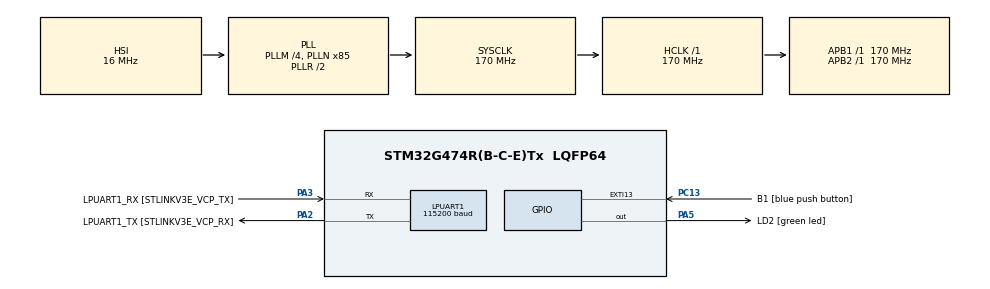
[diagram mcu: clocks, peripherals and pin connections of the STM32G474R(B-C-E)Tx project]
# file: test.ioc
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LPUART1.BaudRate=115200
LPUART1.WordLength=UART_WORDLENGTH_8B
Mcu.Family=STM32G4
Mcu.Name=STM32G474R(B-C-E)Tx
Mcu.Package=LQFP64
NVIC.EXTI15_10_IRQn=true\:0\:0\:false\:false\:true\:true\:true
NVIC.PriorityGroup=NVIC_PRIORITYGROUP_4
PA13.GPIO_Label=T_SWDIO
PA13.Mode=Trace_Asynchronous_SW
PA13.Signal=SYS_JTMS-SWDIO
PA14.GPIO_Label=T_SWCLK
PA14.Mode=Trace_Asynchronous_SW
PA14.Signal=SYS_JTCK-SWCLK
PA2.GPIO_Label=LPUART1_TX [STLINKV3E_VCP_RX]
PA2.Mode=Asynchronous
PA2.Signal=LPUART1_TX
PA3.GPIO_Label=LPUART1_RX [STLINKV3E_VCP_TX]
PA3.Mode=Asynchronous
PA3.Signal=LPUART1_RX
PA5.GPIO_Label=LD2 [green led]
PA5.Signal=GPIO_Output
PB3.GPIO_Label=T_SWO
PB3.Mode=Trace_Asynchronous_SW
PB3.Signal=SYS_JTDO-SWO
PC13.GPIO_Label=B1 [blue push button]
PC13.Signal=GPXTI13
PC14-OSC32_IN.Mode=LSE-External-Oscillator
PC14-OSC32_IN.Signal=RCC_OSC32_IN
PC15-OSC32_OUT.Mode=LSE-External-Oscillator
PC15-OSC32_OUT.Signal=RCC_OSC32_OUT
PF0-OSC_IN.Mode=HSE-External-Oscillator
PF0-OSC_IN.Signal=RCC_OSC_IN
PF1-OSC_OUT.Mode=HSE-External-Oscillator
PF1-OSC_OUT.Signal=RCC_OSC_OUT
ProjectManager.HeapSize=0x200
ProjectManager.StackSize=0x400
ProjectManager.TargetToolchain=Makefile
RCC.ADC12Freq_Value=170000000
RCC.ADC345Freq_Value=170000000
RCC.AHBFreq_Value=170000000
RCC.APB1Freq_Value=170000000
RCC.APB1TimFreq_Value=170000000
RCC.APB2Freq_Value=170000000
RCC.APB2TimFreq_Value=170000000
RCC.CortexFreq_Value=170000000
RCC.EXTERNAL_CLOCK_VALUE=12288000
RCC.HCLKFreq_Value=170000000
RCC.HSE_VALUE=24000000
RCC.HSI48_VALUE=48000000
RCC.HSI_VALUE=16000000
RCC.PLLM=RCC_PLLM_DIV4
RCC.PLLN=85
RCC.RTCClockSelection=RCC_RTCCLKSOURCE_LSE
RCC.SYSCLKFreq_VALUE=170000000
RCC.SYSCLKSource=RCC_SYSCLKSOURCE_PLLCLK
RCC.USBFreq_Value=170000000
RCC.VCOOutputFreq_Value=340000000
VP_SYS_VS_DBSignals.Mode=DisableDeadBatterySignals
board=NUCLEO-G474RE

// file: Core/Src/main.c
/* USER CODE BEGIN Header */
/**
  ******************************************************************************
  * @file           : main.c
  * @brief          : Main program body
  ******************************************************************************
  * @attention
  *
  * <h2><center>&copy; Copyright (c) 2020 STMicroelectronics.
  * All rights reserved.</center></h2>
  *
  * This software component is licensed by ST under BSD 3-Clause license,
  * the "License"; You may not use this file except in compliance with the
  * License. You may obtain a copy of the License at:
  *                        opensource.org/licenses/BSD-3-Clause
  *
  ******************************************************************************
  */
/* USER CODE END Header */
#include "main.h"

/* USER CODE BEGIN Includes */
#include "string.h"
/* USER CODE END Includes */

UART_HandleTypeDef hlpuart1;

void SystemClock_Config(void);
static void MX_GPIO_Init(void);
static void MX_LPUART1_UART_Init(void);

/* USER CODE BEGIN 0 */
int _write(int file, char *ptr, int len)
{
	int DataIdx;

	for (DataIdx = 0; DataIdx < len; DataIdx++)
	{
	   ITM_SendChar( *ptr++ );
	}

	return len;
}

void print_string(char* str)
{
  _write(0, str, strlen(str));
}
/* USER CODE END 0 */

int main(void)
{

  /* MCU Configuration--------------------------------------------------------*/

  /* Reset of all peripherals, Initializes the Flash interface and the Systick. */
  HAL_Init();

  /* Configure the system clock */
  SystemClock_Config();

  /* Initialize all configured peripherals */
  MX_GPIO_Init();
  MX_LPUART1_UART_Init();

  /* Infinite loop */
  while (1)
  {

    /* USER CODE BEGIN 3 */
    print_string("Test string\r\n");
    HAL_Delay(500);
  }
  /* USER CODE END 3 */
}

void SystemClock_Config(void)
{
  RCC_OscInitTypeDef RCC_OscInitStruct = {0};
  RCC_ClkInitTypeDef RCC_ClkInitStruct = {0};
  RCC_PeriphCLKInitTypeDef PeriphClkInit = {0};

  /** Configure the main internal regulator output voltage
  */
  HAL_PWREx_ControlVoltageScaling(PWR_REGULATOR_VOLTAGE_SCALE1_BOOST);
  /** Initializes the RCC Oscillators according to the specified parameters
  * in the RCC_OscInitTypeDef structure.
  */
  RCC_OscInitStruct.OscillatorType = RCC_OSCILLATORTYPE_HSI;
  RCC_OscInitStruct.HSIState = RCC_HSI_ON;
  RCC_OscInitStruct.HSICalibrationValue = RCC_HSICALIBRATION_DEFAULT;
  RCC_OscInitStruct.PLL.PLLState = RCC_PLL_ON;
  RCC_OscInitStruct.PLL.PLLSource = RCC_PLLSOURCE_HSI;
  RCC_OscInitStruct.PLL.PLLM = RCC_PLLM_DIV4;
  RCC_OscInitStruct.PLL.PLLN = 85;
  RCC_OscInitStruct.PLL.PLLP = RCC_PLLP_DIV2;
  RCC_OscInitStruct.PLL.PLLQ = RCC_PLLQ_DIV2;
  RCC_OscInitStruct.PLL.PLLR = RCC_PLLR_DIV2;
  if (HAL_RCC_OscConfig(&RCC_OscInitStruct) != HAL_OK)
  {
    Error_Handler();
  }
  /** Initializes the CPU, AHB and APB buses clocks
  */
  RCC_ClkInitStruct.ClockType = RCC_CLOCKTYPE_HCLK|RCC_CLOCKTYPE_SYSCLK
                              |RCC_CLOCKTYPE_PCLK1|RCC_CLOCKTYPE_PCLK2;
  RCC_ClkInitStruct.SYSCLKSource = RCC_SYSCLKSOURCE_PLLCLK;
  RCC_ClkInitStruct.AHBCLKDivider = RCC_SYSCLK_DIV1;
  RCC_ClkInitStruct.APB1CLKDivider = RCC_HCLK_DIV1;
  RCC_ClkInitStruct.APB2CLKDivider = RCC_HCLK_DIV1;

  if (HAL_RCC_ClockConfig(&RCC_ClkInitStruct, FLASH_LATENCY_4) != HAL_OK)
  {
    Error_Handler();
  }
  /** Initializes the peripherals clocks
  */
  PeriphClkInit.PeriphClockSelection = RCC_PERIPHCLK_LPUART1;
  PeriphClkInit.Lpuart1ClockSelection = RCC_LPUART1CLKSOURCE_PCLK1;
  if (HAL_RCCEx_PeriphCLKConfig(&PeriphClkInit) != HAL_OK)
  {
    Error_Handler();
  }
}

static void MX_LPUART1_UART_Init(void)
{

  hlpuart1.Instance = LPUART1;
  hlpuart1.Init.BaudRate = 115200;
  hlpuart1.Init.WordLength = UART_WORDLENGTH_8B;
  hlpuart1.Init.StopBits = UART_STOPBITS_1;
  hlpuart1.Init.Parity = UART_PARITY_NONE;
  hlpuart1.Init.Mode = UART_MODE_TX_RX;
  hlpuart1.Init.HwFlowCtl = UART_HWCONTROL_NONE;
  hlpuart1.Init.OneBitSampling = UART_ONE_BIT_SAMPLE_DISABLE;
  hlpuart1.Init.ClockPrescaler = UART_PRESCALER_DIV1;
  hlpuart1.AdvancedInit.AdvFeatureInit = UART_ADVFEATURE_NO_INIT;
  if (HAL_UART_Init(&hlpuart1) != HAL_OK)
  {
    Error_Handler();
  }
  if (HAL_UARTEx_SetTxFifoThreshold(&hlpuart1, UART_TXFIFO_THRESHOLD_1_8) != HAL_OK)
  {
    Error_Handler();
  }
  if (HAL_UARTEx_SetRxFifoThreshold(&hlpuart1, UART_RXFIFO_THRESHOLD_1_8) != HAL_OK)
  {
    Error_Handler();
  }
  if (HAL_UARTEx_DisableFifoMode(&hlpuart1) != HAL_OK)
  {
    Error_Handler();
  }

}

static void MX_GPIO_Init(void)
{
  GPIO_InitTypeDef GPIO_InitStruct = {0};

  /* GPIO Ports Clock Enable */
  __HAL_RCC_GPIOC_CLK_ENABLE();
  __HAL_RCC_GPIOF_CLK_ENABLE();
  __HAL_RCC_GPIOA_CLK_ENABLE();
  __HAL_RCC_GPIOB_CLK_ENABLE();

  /*Configure GPIO pin Output Level */
  HAL_GPIO_WritePin(LD2_GPIO_Port, LD2_Pin, GPIO_PIN_RESET);

  /*Configure GPIO pin : B1_Pin */
  GPIO_InitStruct.Pin = B1_Pin;
  GPIO_InitStruct.Mode = GPIO_MODE_IT_RISING;
  GPIO_InitStruct.Pull = GPIO_NOPULL;
  HAL_GPIO_Init(B1_GPIO_Port, &GPIO_InitStruct);

  /*Configure GPIO pin : LD2_Pin */
  GPIO_InitStruct.Pin = LD2_Pin;
  GPIO_InitStruct.Mode = GPIO_MODE_OUTPUT_PP;
  GPIO_InitStruct.Pull = GPIO_NOPULL;
  GPIO_InitStruct.Speed = GPIO_SPEED_FREQ_LOW;
  HAL_GPIO_Init(LD2_GPIO_Port, &GPIO_InitStruct);

  /* EXTI interrupt init*/
  HAL_NVIC_SetPriority(EXTI15_10_IRQn, 0, 0);
  HAL_NVIC_EnableIRQ(EXTI15_10_IRQn);

}

void Error_Handler(void)
{
  __disable_irq();
  while (1)
  {
  }
}

/************************ (C) COPYRIGHT STMicroelectronics *****END OF FILE****/
